VERSION ""

NS_ :

BS_:

BU_: BKU_Joystick BKU KVU
VAL_TABLE_ kvu_mainState_errorCode 3343 "ABS: RR Failure" 3342 "ABS: RR Warning" 3341 "ABS: RR Wiring" 3340 "ABS: RR Hardware" 3339 "ABS: RL Failure" 3338 "ABS: RL Warning" 3337 "ABS: RL Wiring" 3336 "ABS: RL Hardware" 3335 "ABS: FR Failure" 3334 "ABS: FR Warning" 3333 "ABS: FR Wiring" 3332 "ABS: FR Hardware" 3331 "ABS: FL Failure" 3330 "ABS: FL Warning" 3329 "ABS: FL Wiring" 3328 "ABS: FL Hardware" 2593 "REAR STEERING: FAULT" 2592 "REAR STEERING: OFFLINE" 2563 "REAR STEERING: OVERHEAT" 2562 "REAR STEERING: WARNING" 2337 "FRONT STEERING: FAULT" 2336 "FRONT STEERING: OFFLINE" 2307 "FRONT STEERING: OVERHEAT" 2306 "FRONT STEERING: WARNING" 1796 "EEPROM: Verification" 1795 "EEPROM: Init timeout" 1794 "EEPROM: Nullptr" 1793 "EEPROM: Hardware" 1792 "EEPROM: CRC" 1536 "LIGHTS CONTROL: Lights pin error" 256 "Separator" ;
VAL_TABLE_ Peripheral_RedButton 3 "Not avialable" 2 "Error" 1 "Pressed" 0 "Not pressed" ;
VAL_TABLE_ Doors 3 "Not Avialable" 2 "Error" 1 "Open" 0 "Close" ;
VAL_TABLE_ kvu_Workmodes 2 "Driver control" 1 "Local control from VMU commands" 0 "Controlled from BKU" ;
VAL_TABLE_ bku_lightsTurnMode 3 "Alarm" 2 "Right" 1 "Left" 0 "Disabled" ;
VAL_TABLE_ kvu_errorCode_priority 1 "critical" 0 "warning" ;
VAL_TABLE_ kvu_errorCode_source 17 "Power_management" 16 "Motor_drive" 15 "Voltage_monitoring" 14 "Suspension" 13 "Hydraulic_brakes" 12 "Charging" 11 "IO_lib_errors" 10 "Discrete_input" 9 "ABS" 8 "System" 7 "Parking_brake" 6 "Steering_rear" 5 "Steering_front" 4 "J1939" 3 "EEPROM" 2 "Lights" 1 "Canopen" 0 "Undefined" ;

BO_ 3221225472 VECTOR__INDEPENDENT_SIG_MSG: 0 Vector__XXX
 SG_ kvu_sideDoor_Right : 0|2@1+ (1,0) [0|3] "" Vector__XXX
 SG_ kvu_sideDoor_Left : 0|2@1+ (1,0) [0|3] "" Vector__XXX

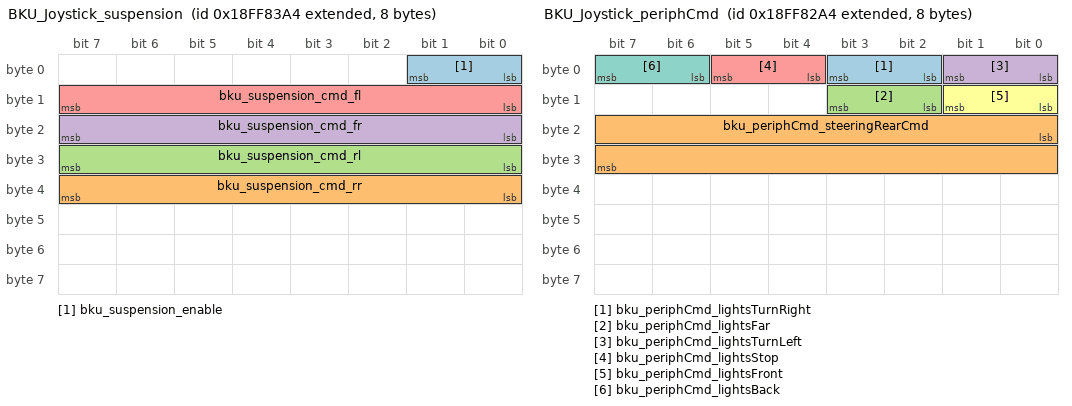
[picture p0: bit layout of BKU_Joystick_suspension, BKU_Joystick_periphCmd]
BO_ 2566882212 BKU_Joystick_suspension: 8 BKU_Joystick
 SG_ bku_suspension_enable : 0|2@1+ (1,0) [0|3] "" Vector__XXX
 SG_ bku_suspension_cmd_rr : 32|8@1+ (2,-250) [-250|250] "mm" Vector__XXX
 SG_ bku_suspension_cmd_rl : 24|8@1+ (2,-250) [-250|250] "mm" Vector__XXX
 SG_ bku_suspension_cmd_fr : 16|8@1+ (2,-250) [-250|250] "mm" Vector__XXX
 SG_ bku_suspension_cmd_fl : 8|8@1+ (2,-250) [-250|250] "mm" Vector__XXX

BO_ 2566885540 BKU_Joystick_resetErrors: 8 BKU_Joystick
 SG_ bku_resetErrors_bits : 0|40@1+ (1,0) [0|1099511627775] "" Vector__XXX

BO_ 2566881956 BKU_Joystick_periphCmd: 8 BKU_Joystick
 SG_ bku_periphCmd_lightsTurnRight : 2|2@1+ (1,0) [0|3] "" Vector__XXX
 SG_ bku_periphCmd_steeringRearCmd : 16|16@1+ (0.01,-100) [-100|100] "%" Vector__XXX
 SG_ bku_periphCmd_lightsFar : 10|2@1+ (1,0) [0|3] "" Vector__XXX
 SG_ bku_periphCmd_lightsTurnLeft : 0|2@1+ (1,0) [0|3] "" Vector__XXX
 SG_ bku_periphCmd_lightsStop : 4|2@1+ (1,0) [0|3] "" Vector__XXX
 SG_ bku_periphCmd_lightsFront : 8|2@1+ (1,0) [0|3] "" Vector__XXX
 SG_ bku_periphCmd_lightsBack : 6|2@1+ (1,0) [0|3] "" Vector__XXX

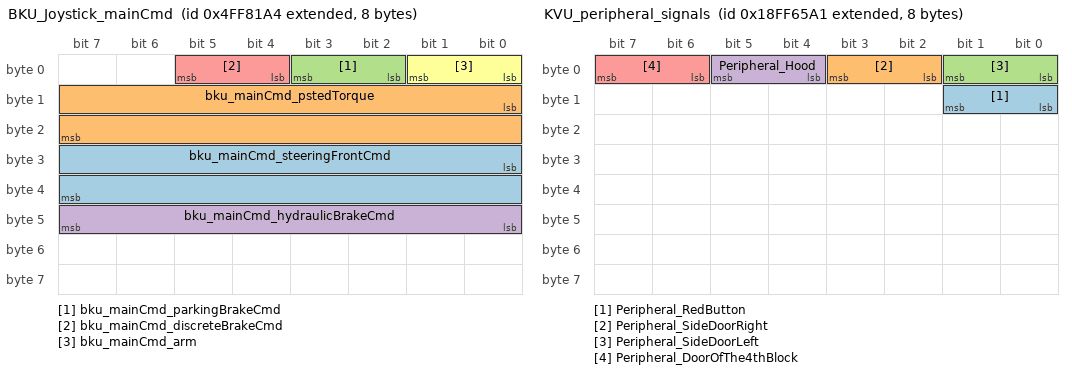
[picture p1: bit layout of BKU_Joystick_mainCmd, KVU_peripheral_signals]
BO_ 2231337380 BKU_Joystick_mainCmd: 8 BKU_Joystick
 SG_ bku_mainCmd_steeringFrontCmd : 24|16@1+ (0.01,-100) [-100|100] "%" Vector__XXX
 SG_ bku_mainCmd_pstedTorque : 8|16@1+ (0.01,-100) [-100|100] "%" Vector__XXX
 SG_ bku_mainCmd_parkingBrakeCmd : 2|2@1+ (1,0) [0|3] "" Vector__XXX
 SG_ bku_mainCmd_hydraulicBrakeCmd : 40|8@1+ (0.4,0) [0|100] "%" Vector__XXX
 SG_ bku_mainCmd_discreteBrakeCmd : 4|2@1+ (1,0) [0|3] "" Vector__XXX
 SG_ bku_mainCmd_arm : 0|2@1+ (1,0) [0|3] "" Vector__XXX

BO_ 2566874529 KVU_peripheral_signals: 8 KVU
 SG_ Peripheral_RedButton : 8|2@1+ (1,0) [0|3] "" Vector__XXX
 SG_ Peripheral_SideDoorRight : 2|2@1+ (1,0) [0|3] "" Vector__XXX
 SG_ Peripheral_SideDoorLeft : 0|2@1+ (1,0) [0|3] ""  BKU
 SG_ Peripheral_Hood : 4|2@1+ (1,0) [0|3] ""  BKU
 SG_ Peripheral_DoorOfThe4thBlock : 6|2@1+ (1,0) [0|3] ""  BKU

BO_ 2566885541 BKU_resetErrors: 8 BKU
 SG_ bku_resetErrors_bits : 0|40@1+ (1,0) [0|1099511627775] ""  KVU

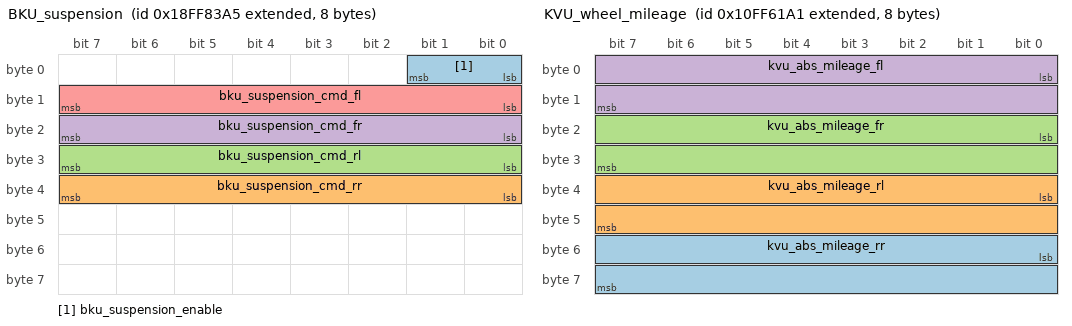
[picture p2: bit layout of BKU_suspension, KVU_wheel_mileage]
BO_ 2566882213 BKU_suspension: 8 BKU
 SG_ bku_suspension_enable : 0|2@1+ (1,0) [0|3] ""  KVU
 SG_ bku_suspension_cmd_rr : 32|8@1+ (2,-250) [-250|250] "mm"  KVU
 SG_ bku_suspension_cmd_rl : 24|8@1+ (2,-250) [-250|250] "mm"  KVU
 SG_ bku_suspension_cmd_fr : 16|8@1+ (2,-250) [-250|250] "mm"  KVU
 SG_ bku_suspension_cmd_fl : 8|8@1+ (2,-250) [-250|250] "mm"  KVU

BO_ 2432655777 KVU_wheel_mileage: 8 KVU
 SG_ kvu_abs_mileage_rr : 48|16@1+ (1,0) [0|32767] ""  BKU
 SG_ kvu_abs_mileage_rl : 32|16@1+ (1,0) [0|32767] ""  BKU
 SG_ kvu_abs_mileage_fr : 16|16@1+ (1,0) [0|32767] ""  BKU
 SG_ kvu_abs_mileage_fl : 0|16@1+ (1,0) [0|32767] ""  BKU

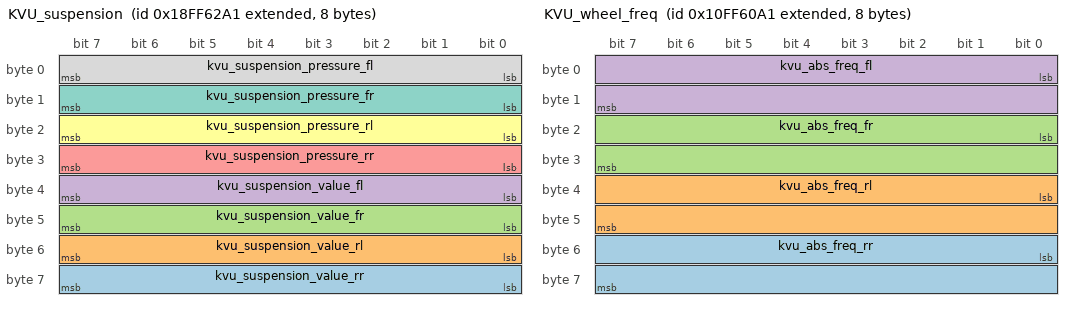
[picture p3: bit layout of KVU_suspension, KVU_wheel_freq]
BO_ 2566873761 KVU_suspension: 8 KVU
 SG_ kvu_suspension_value_rr : 56|8@1+ (2,-250) [-250|260] "mm"  BKU
 SG_ kvu_suspension_value_rl : 48|8@1+ (2,-250) [-250|260] "mm"  BKU
 SG_ kvu_suspension_value_fr : 40|8@1+ (2,-250) [-250|260] "mm"  BKU
 SG_ kvu_suspension_value_fl : 32|8@1+ (2,-250) [-250|260] "mm"  BKU
 SG_ kvu_suspension_pressure_rr : 24|8@1+ (0.1,0) [0|25] "atm"  BKU
 SG_ kvu_suspension_pressure_rl : 16|8@1+ (0.1,0) [0|25] "atm"  BKU
 SG_ kvu_suspension_pressure_fr : 8|8@1+ (0.1,0) [0|25] "atm"  BKU
 SG_ kvu_suspension_pressure_fl : 0|8@1+ (0.1,0) [0|25] "atm"  BKU

BO_ 2432655521 KVU_wheel_freq: 8 KVU
 SG_ kvu_abs_freq_rr : 48|16@1+ (0.002,-50) [-50|81.07] "Hz"  BKU
 SG_ kvu_abs_freq_rl : 32|16@1+ (0.002,-50) [-50|81.07] "Hz"  BKU
 SG_ kvu_abs_freq_fr : 16|16@1+ (0.002,-50) [-50|81.07] "Hz"  BKU
 SG_ kvu_abs_freq_fl : 0|16@1+ (0.002,-50) [-50|81.07] "Hz"  BKU

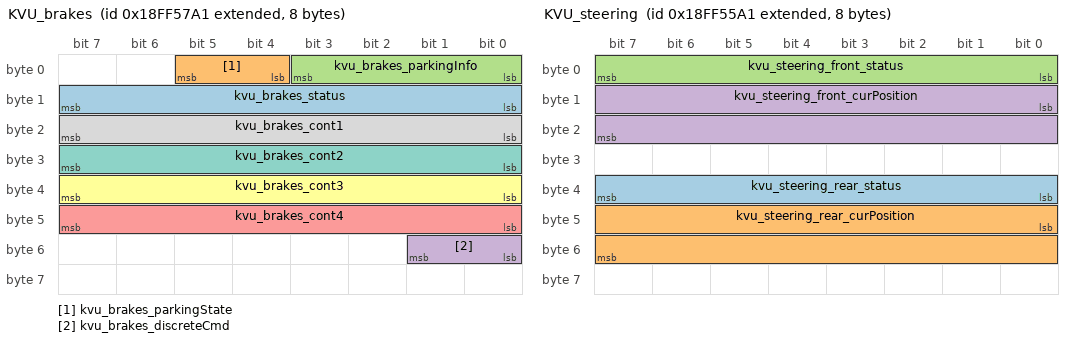
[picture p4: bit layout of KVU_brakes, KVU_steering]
BO_ 2566870945 KVU_brakes: 8 KVU
 SG_ kvu_brakes_status : 8|8@1+ (1,0) [0|0] ""  BKU
 SG_ kvu_brakes_parkingState : 4|2@1+ (1,0) [0|3] ""  BKU
 SG_ kvu_brakes_parkingInfo : 0|4@1+ (1,0) [0|15] ""  BKU
 SG_ kvu_brakes_discreteCmd : 48|2@1+ (1,0) [0|3] ""  BKU
 SG_ kvu_brakes_cont4 : 40|8@1+ (1,0) [0|255] "%"  BKU
 SG_ kvu_brakes_cont3 : 32|8@1+ (1,0) [0|255] "%"  BKU
 SG_ kvu_brakes_cont2 : 24|8@1+ (1,0) [0|255] "%"  BKU
 SG_ kvu_brakes_cont1 : 16|8@1+ (1,0) [0|255] "%"  BKU

BO_ 2566870433 KVU_steering: 8 KVU
 SG_ kvu_steering_rear_status : 32|8@1+ (1,0) [0|255] ""  BKU
 SG_ kvu_steering_rear_curPosition : 40|16@1+ (1,-30000) [-30000|35535] ""  BKU
 SG_ kvu_steering_front_status : 0|8@1+ (1,0) [0|255] ""  BKU
 SG_ kvu_steering_front_curPosition : 8|16@1+ (1,-30000) [-30000|35535] ""  BKU

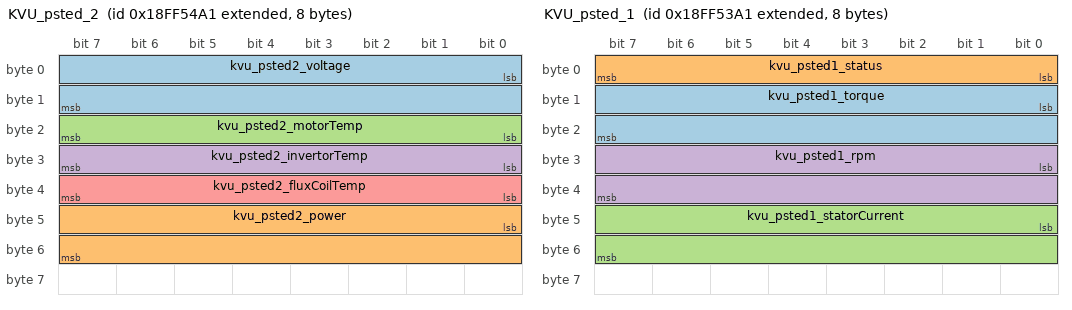
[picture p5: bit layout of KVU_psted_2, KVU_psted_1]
BO_ 2566870177 KVU_psted_2: 8 KVU
 SG_ kvu_psted2_voltage : 0|16@1+ (0.1,0) [0|6553.5] "V"  BKU
 SG_ kvu_psted2_power : 40|16@1+ (0.1,-2000) [-2000|4553.5] "kW"  BKU
 SG_ kvu_psted2_motorTemp : 16|8@1+ (1,-40) [-40|210] "°C"  BKU
 SG_ kvu_psted2_invertorTemp : 24|8@1+ (1,-40) [-40|210] "°C"  BKU
 SG_ kvu_psted2_fluxCoilTemp : 32|8@1+ (1,-40) [-40|210] "°C"  BKU

BO_ 2566869921 KVU_psted_1: 8 KVU
 SG_ kvu_psted1_torque : 8|16@1+ (0.01,-100) [-100|555.35] "%"  BKU
 SG_ kvu_psted1_status : 0|8@1+ (1,0) [0|255] ""  BKU
 SG_ kvu_psted1_statorCurrent : 40|16@1+ (0.1,-2000) [-2000|4553.5] "A"  BKU
 SG_ kvu_psted1_rpm : 24|16@1+ (0.25,-8000) [-8000|8383.75] "rpm"  BKU

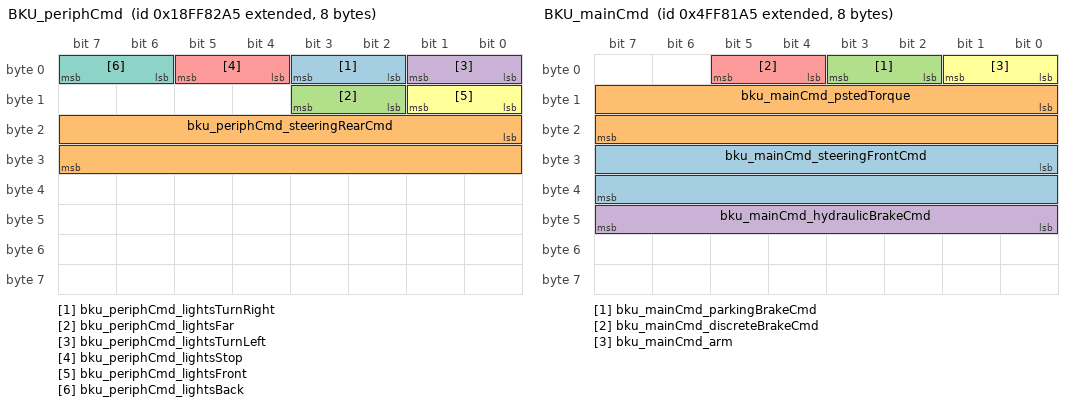
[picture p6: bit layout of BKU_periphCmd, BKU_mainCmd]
BO_ 2566881957 BKU_periphCmd: 8 BKU
 SG_ bku_periphCmd_lightsTurnRight : 2|2@1+ (1,0) [0|3] "" Vector__XXX
 SG_ bku_periphCmd_steeringRearCmd : 16|16@1+ (0.01,-100) [-100|100] "%"  KVU
 SG_ bku_periphCmd_lightsFar : 10|2@1+ (1,0) [0|3] ""  KVU
 SG_ bku_periphCmd_lightsTurnLeft : 0|2@1+ (1,0) [0|3] ""  KVU
 SG_ bku_periphCmd_lightsStop : 4|2@1+ (1,0) [0|3] ""  KVU
 SG_ bku_periphCmd_lightsFront : 8|2@1+ (1,0) [0|3] ""  KVU
 SG_ bku_periphCmd_lightsBack : 6|2@1+ (1,0) [0|3] ""  KVU

BO_ 2231337381 BKU_mainCmd: 8 BKU
 SG_ bku_mainCmd_steeringFrontCmd : 24|16@1+ (0.01,-100) [-100|100] "%"  KVU
 SG_ bku_mainCmd_pstedTorque : 8|16@1+ (0.01,-100) [-100|100] "%"  KVU
 SG_ bku_mainCmd_parkingBrakeCmd : 2|2@1+ (1,0) [0|3] ""  KVU
 SG_ bku_mainCmd_hydraulicBrakeCmd : 40|8@1+ (0.4,0) [0|100] "%"  KVU
 SG_ bku_mainCmd_discreteBrakeCmd : 4|2@1+ (1,0) [0|3] ""  KVU
 SG_ bku_mainCmd_arm : 0|2@1+ (1,0) [0|3] ""  KVU

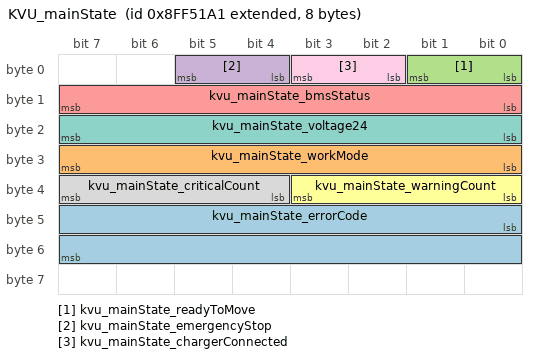
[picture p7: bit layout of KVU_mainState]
BO_ 2298433953 KVU_mainState: 8 KVU
 SG_ kvu_mainState_errorCode : 40|16@1+ (1,0) [0|65535] "" Vector__XXX
 SG_ kvu_mainState_workMode : 24|8@1+ (1,0) [0|255] ""  BKU
 SG_ kvu_mainState_readyToMove : 0|2@1+ (1,0) [0|3] ""  BKU
 SG_ kvu_mainState_emergencyStop : 4|2@1+ (1,0) [0|3] ""  BKU
 SG_ kvu_mainState_bmsStatus : 8|8@1+ (1,0) [0|255] ""  BKU
 SG_ kvu_mainState_warningCount : 32|4@1+ (1,0) [0|15] ""  BKU
 SG_ kvu_mainState_voltage24 : 16|8@1+ (0.1,10) [10|34] "V"  BKU
 SG_ kvu_mainState_criticalCount : 36|4@1+ (1,0) [0|15] ""  BKU
 SG_ kvu_mainState_chargerConnected : 2|2@1+ (1,0) [0|3] ""  BKU

CM_ BO_ 3221225472 "This is a message for not used signals, created by Vector CANdb++ DBC OLE DB Provider.";
CM_ SG_ 2566874529 Peripheral_RedButton "Состояние кнопки аварийной остановки";
CM_ SG_ 2566874529 Peripheral_SideDoorRight "Состояние дверцы правого борта (шкаф управления)";
CM_ SG_ 2566874529 Peripheral_SideDoorLeft "Состояние дверцы левого борта (ТАБ)";
CM_ SG_ 2566874529 Peripheral_Hood "Состоние капота";
CM_ SG_ 2566874529 Peripheral_DoorOfThe4thBlock "Состоние дверцы 4го блока";
CM_ SG_ 2566870945 kvu_brakes_status "Текущий статус контроллера системы плавного торможения";
CM_ SG_ 2566870945 kvu_brakes_parkingState "Состояние стояночного тормоза";
CM_ SG_ 2566870945 kvu_brakes_parkingInfo "Текущий статус блока управления электропривода стояночного тормоза ";
CM_ SG_ 2566870433 kvu_steering_rear_status "Текущий статус электропривода рулевой рейки задней оси ";
CM_ SG_ 2566870433 kvu_steering_rear_curPosition "Текущее положение электропривода рулевой рейки задней оси";
CM_ SG_ 2566870433 kvu_steering_front_status "Текущий статус электропривода рулевой рейки передней оси ";
CM_ SG_ 2566870433 kvu_steering_front_curPosition "Текущее положение электропривода рулевой рейки передней оси";
CM_ SG_ 2566870177 kvu_psted2_voltage "Напряжение на звене постоянного тока ПСТЭД";
CM_ SG_ 2566870177 kvu_psted2_power "Мощность тягового двигателя";
CM_ SG_ 2566870177 kvu_psted2_motorTemp "Температура тягового двигателя";
CM_ SG_ 2566870177 kvu_psted2_invertorTemp "Температура силового преобразователя тягового двигателя";
CM_ SG_ 2566870177 kvu_psted2_fluxCoilTemp "Температура обмотки возбуждения тягового двигателя,";
CM_ SG_ 2566869921 kvu_psted1_torque "Текущее значение момента, развиваемого двигателем";
CM_ SG_ 2566869921 kvu_psted1_status "Текущий статус ПСТЭД";
CM_ SG_ 2566869921 kvu_psted1_statorCurrent "Ток статора двигателя";
CM_ SG_ 2566869921 kvu_psted1_rpm "Текущая частота вращения двигателя";
CM_ SG_ 2298433953 kvu_mainState_errorCode "Код ошибки КВУ";
CM_ SG_ 2298433953 kvu_mainState_workMode "Режим работы КВУ";
CM_ SG_ 2298433953 kvu_mainState_emergencyStop "Аварийный останов";
CM_ SG_ 2298433953 kvu_mainState_chargerConnected "Charger is connected to the vehicle";
BA_DEF_ SG_  "SigType" ENUM  "Default","Range","RangeSigned","ASCII","Discrete","Control","ReferencePGN","DTC","StringDelimiter","StringLength","StringLengthControl","MessageCounter","MessageChecksum";
BA_DEF_ SG_  "GenSigEVName" STRING ;
BA_DEF_ SG_  "GenSigILSupport" ENUM  "No","Yes";
BA_DEF_ SG_  "GenSigSendType" ENUM  "Cyclic","OnWrite","OnWriteWithRepetition","OnChange","OnChangeWithRepetition","IfActive","IfActiveWithRepetition","NoSigSendType";
BA_DEF_ SG_  "GenSigStartValue" INT 0 2147483647;
BA_DEF_ BO_  "GenMsgILSupport" ENUM  "No","Yes";
BA_DEF_ BU_  "NmStationAddress" INT 0 255;
BA_DEF_ BO_  "GenMsgSendType" ENUM  "cyclic","NotUsed","IfActive","NotUsed","NotUsed","NotUsed","NotUsed","NotUsed","noMsgSendType";
BA_DEF_ BO_  "GenMsgRequestable" INT 0 1;
BA_DEF_  "DBName" STRING ;
BA_DEF_  "BusType" STRING ;
BA_DEF_  "ProtocolType" STRING ;
BA_DEF_ BO_  "VFrameFormat" ENUM  "StandardCAN","ExtendedCAN","reserved","J1939PG";
BA_DEF_DEF_  "SigType" "Default";
BA_DEF_DEF_  "GenSigEVName" "Env@Nodename_@Signame";
BA_DEF_DEF_  "GenSigILSupport" "Yes";
BA_DEF_DEF_  "GenSigSendType" "NoSigSendType";
BA_DEF_DEF_  "GenSigStartValue" 0;
BA_DEF_DEF_  "GenMsgILSupport" "Yes";
BA_DEF_DEF_  "NmStationAddress" 254;
BA_DEF_DEF_  "GenMsgSendType" "noMsgSendType";
BA_DEF_DEF_  "GenMsgRequestable" 1;
BA_DEF_DEF_  "DBName" "";
BA_DEF_DEF_  "BusType" "CAN";
BA_DEF_DEF_  "ProtocolType" "J1939";
BA_DEF_DEF_  "VFrameFormat" "J1939PG";
BA_ "DBName" "N1_CAN2";
BA_ "NmStationAddress" BU_ BKU_Joystick 164;
BA_ "NmStationAddress" BU_ BKU 165;
BA_ "NmStationAddress" BU_ KVU 161;
BA_ "GenSigStartValue" SG_ 2566882212 bku_suspension_cmd_rr 125;
BA_ "GenSigStartValue" SG_ 2566882212 bku_suspension_cmd_rl 125;
BA_ "GenSigStartValue" SG_ 2566882212 bku_suspension_cmd_fr 125;
BA_ "GenSigStartValue" SG_ 2566882212 bku_suspension_cmd_fl 125;
BA_ "GenSigStartValue" SG_ 2566881956 bku_periphCmd_steeringRearCmd 10000;
BA_ "GenSigStartValue" SG_ 2231337380 bku_mainCmd_steeringFrontCmd 10000;
BA_ "GenSigStartValue" SG_ 2231337380 bku_mainCmd_pstedTorque 10000;
BA_ "GenSigStartValue" SG_ 2566882213 bku_suspension_cmd_rr 125;
BA_ "GenSigStartValue" SG_ 2566882213 bku_suspension_cmd_rl 125;
BA_ "GenSigStartValue" SG_ 2566882213 bku_suspension_cmd_fr 125;
BA_ "GenSigStartValue" SG_ 2566882213 bku_suspension_cmd_fl 125;
BA_ "GenSigStartValue" SG_ 2566873761 kvu_suspension_value_rr 125;
BA_ "GenSigStartValue" SG_ 2566873761 kvu_suspension_value_rl 125;
BA_ "GenSigStartValue" SG_ 2566873761 kvu_suspension_value_fr 125;
BA_ "GenSigStartValue" SG_ 2566873761 kvu_suspension_value_fl 125;
BA_ "GenSigStartValue" SG_ 2432655521 kvu_abs_freq_rr 25000;
BA_ "GenSigStartValue" SG_ 2432655521 kvu_abs_freq_rl 25000;
BA_ "GenSigStartValue" SG_ 2432655521 kvu_abs_freq_fr 25000;
BA_ "GenSigStartValue" SG_ 2432655521 kvu_abs_freq_fl 25000;
BA_ "GenSigStartValue" SG_ 2566870433 kvu_steering_rear_curPosition 30000;
BA_ "GenSigStartValue" SG_ 2566870433 kvu_steering_front_curPosition 30000;
BA_ "GenSigStartValue" SG_ 2566870177 kvu_psted2_power 20000;
BA_ "GenSigStartValue" SG_ 2566870177 kvu_psted2_motorTemp 40;
BA_ "GenSigStartValue" SG_ 2566870177 kvu_psted2_invertorTemp 40;
BA_ "GenSigStartValue" SG_ 2566870177 kvu_psted2_fluxCoilTemp 40;
BA_ "GenSigStartValue" SG_ 2566869921 kvu_psted1_torque 10000;
BA_ "GenSigStartValue" SG_ 2566869921 kvu_psted1_statorCurrent 20000;
BA_ "GenSigStartValue" SG_ 2566869921 kvu_psted1_rpm 32000;
BA_ "GenSigStartValue" SG_ 2566881957 bku_periphCmd_steeringRearCmd 10000;
BA_ "GenSigStartValue" SG_ 2231337381 bku_mainCmd_steeringFrontCmd 10000;
BA_ "GenSigStartValue" SG_ 2231337381 bku_mainCmd_pstedTorque 10000;
VAL_ 2566874529 Peripheral_RedButton 3 "Not avialable" 2 "Error" 1 "Pressed" 0 "Not pressed" ;
VAL_ 2566874529 Peripheral_SideDoorRight 3 "Not Avialable" 2 "Error" 1 "Open" 0 "Close" ;
VAL_ 2566874529 Peripheral_SideDoorLeft 3 "Not Avialable" 2 "Error" 1 "Open" 0 "Close" ;
VAL_ 2566874529 Peripheral_Hood 3 "Not Avialable" 2 "Error" 1 "Open" 0 "Close" ;
VAL_ 2566874529 Peripheral_DoorOfThe4thBlock 3 "Not Avialable" 2 "Error" 1 "Open" 0 "Close" ;
VAL_ 2298433953 kvu_mainState_errorCode 7175 "0: PAYLOAD: PAYLOAD_WARNING_4_KG" 7174 "0: PAYLOAD: PAYLOAD_WARNING_3_KG" 7173 "0: PAYLOAD: PAYLOAD_WARNING_2_KG" 7172 "0: PAYLOAD: PAYLOAD_WARNING_1_KG" 7170 "0: PAYLOAD: CALIBRATION_PROCESS" 7169 "0: PAYLOAD: CALIBRATION_DATA" 7168 "0: PAYLOAD: OVERWEIGHT " 6957 "1: DIO: BRAKE_VALVE_2_9" 6956 "1: DIO: BRAKE_VALVE_1_8" 6955 "1: DIO: BRAKE_PUMP" 6946 "1: DIO: START_PSTED" 6945 "1: DIO: CHARGE_CP" 6944 "1: DIO: PARKING_BRAKE" 6926 "0: DIO: CHARGE_LED" 6922 "0: DIO: SUSP_VALVE_DOWN_4" 6921 "0: DIO: SUSP_VALVE_DOWN_3" 6920 "0: DIO: SUSP_VALVE_DOWN_2" 6919 "0: DIO: SUSP_VALVE_DOWN_1" 6918 "0: DIO: SUSP_VALVE_UP_4" 6917 "0: DIO: SUSP_VALVE_UP_3" 6916 "0: DIO: SUSP_VALVE_UP_2" 6915 "0: DIO: SUSP_VALVE_UP_1" 6688 "1: T15_CONTROL: HARDWARE" 6145 "0: COOLING_FAN: WRONG_SETTINGS" 6144 "0: COOLING_FAN: HARDWARE_ERROR" 5408 "1: MAINFSM: BKU_LOST_IN_ARMED" 5121 "0: POWER: BKU_turnoff pin" 5120 "0: POWER: Mass relay pin" 4906 "1: PSTED: Other errors" 4903 "1: PSTED: Precharge fault" 4902 "1: PSTED: Software and config" 4901 "1: PSTED: Contactor fault" 4900 "1: PSTED: Phys limits" 4899 "1: PSTED: Overheat" 4898 "1: PSTED: Emergency stop" 4897 "1: PSTED: Hardware fault" 4896 "1: PSTED: Offline" 4886 "0: PSTED: ISOLATION_FAULT" 4885 "0: PSTED: BMS_UNDERVOLTAGE" 4884 "0: PSTED: Other warning" 4883 "0: PSTED: High voltage warning" 4882 "0: PSTED: Sensor warning" 4881 "0: PSTED: Overheat warning" 4880 "0: PSTED: Contactor warning" 4614 "0: VOLTAGE: 12V OVERVOLTAGE" 4613 "0: VOLTAGE: 12V UNDERVOLTAGE" 4612 "0: VOLTAGE: 12V HARDWARE" 4610 "0: VOLTAGE: 24V OVERVOLTAGE" 4609 "0: VOLTAGE: 24V UNDERVOLTAGE" 4608 "0: VOLTAGE: 24V HARDWARE" 4354 "0: SUSPENSION: Height timeout" 4353 "0: SUSPENSION: Pressure limit" 4352 "0: SUSPENSION: Hardware fault" 4136 "1: CHARGING: BMS_CRITICAL_ERROR" 4128 "1: CHARGING: BZU_OFFLINE" 4103 "0: CHARGING: BZU_COMMUNICATION" 4102 "0: CHARGING: BZU_INPUT_VOLTAGE" 4101 "0: CHARGING: BZU_OVERHEAT" 4100 "0: CHARGING: BZU_HARDWARE" 4099 "0: CHARGING: BMS_OFFLINE" 3874 "1: IOLIB ERRORS: ERROR_FPU" 3872 "1: IOLIB ERRORS: ERROR_FATAL" 3845 "0: IOLIB ERRORS: WARNING_RAM" 3844 "0: IOLIB ERRORS: WARNING_FLASH" 3843 "0: IOLIB ERRORS: CFG_FLASH" 3841 "0: IOLIB ERRORS: ERROR_NON_FATAL" 3618 "1: DISCRETE INPUTS: Brake fluid" 3616 "1: DISCRETE INPUTS: Red button" 3585 "0: DISCRETE INPUTS: Antifreeze" 3343 "0: ABS: RR Failure" 3342 "0: ABS: RR Warning" 3341 "0: ABS: RR Wiring" 3340 "0: ABS: RR Hardware" 3339 "0: ABS: RL Failure" 3338 "0: ABS: RL Warning" 3337 "0: ABS: RL Wiring" 3336 "0: ABS: RL Hardware" 3335 "0: ABS: FR Failure" 3334 "0: ABS: FR Warning" 3333 "0: ABS: FR Wiring" 3332 "0: ABS: FR Hardware" 3331 "0: ABS: FL Failure" 3330 "0: ABS: FL Warning" 3329 "0: ABS: FL Wiring" 3328 "0: ABS: FL Hardware" 2593 "0: REAR STEERING: FAULT" 2592 "0: REAR STEERING: OFFLINE" 2563 "1: REAR STEERING: OVERHEAT" 2562 "1: REAR STEERING: WARNING" 2337 "0: FRONT STEERING: FAULT" 2336 "0: FRONT STEERING: OFFLINE" 2307 "1: FRONT STEERING: OVERHEAT" 2306 "1: FRONT STEERING: WARNING" 1796 "0: EEPROM: Verification" 1795 "1: EEPROM: Init timeout" 1794 "0: EEPROM: Nullptr" 1793 "0: EEPROM: Hardware" 1792 "0: EEPROM: CRC" 1536 "0: LIGHTS CONTROL: Lights pin" 256 "Separator" ;
VAL_ 2298433953 kvu_mainState_workMode 2 "Driver control" 1 "Local control from VMU commands" 0 "Controlled from BKU" ;
